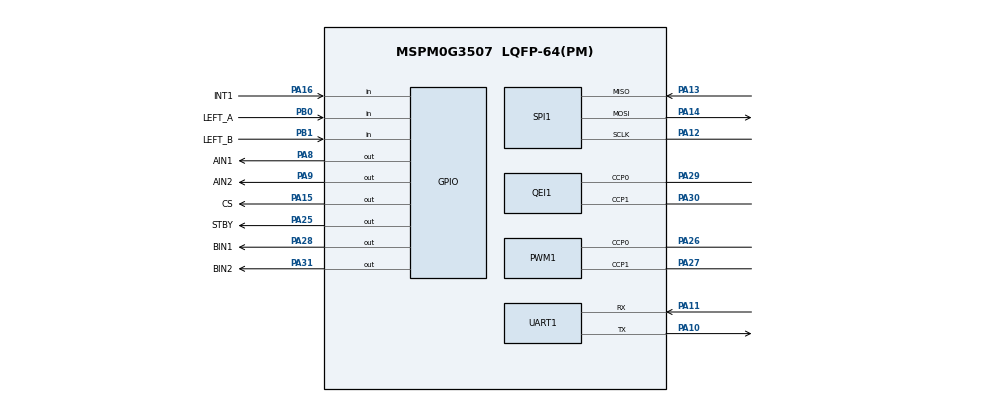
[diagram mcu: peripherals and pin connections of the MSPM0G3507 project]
//@cliArgs --device "MSPM0G350X" --package "LQFP-64(PM)" --part "Default"
//@v2CliArgs --device "MSPM0G3507" --package "LQFP-64(PM)"

/**
 * Import the modules used in this configuration.
 */
const SYSCTL = scripting.addModule("/ti/driverlib/SYSCTL");
const GPIO   = scripting.addModule("/ti/driverlib/GPIO", {}, false);
const GPIO1  = GPIO.addInstance();
const GPIO2  = GPIO.addInstance();
const GPIO3  = GPIO.addInstance();
const PWM    = scripting.addModule("/ti/driverlib/PWM", {}, false);
const PWM1   = PWM.addInstance();
const QEI    = scripting.addModule("/ti/driverlib/QEI", {}, false);
const QEI1   = QEI.addInstance();
const SPI    = scripting.addModule("/ti/driverlib/SPI", {}, false);
const SPI1   = SPI.addInstance();
const TIMER  = scripting.addModule("/ti/driverlib/TIMER", {}, false);
const TIMER1 = TIMER.addInstance();
const TIMER2 = TIMER.addInstance();
const UART   = scripting.addModule("/ti/driverlib/UART", {}, false);
const UART1  = UART.addInstance();
const ProjectConfig = scripting.addModule("/ti/project_config/ProjectConfig");

/**
 * Write custom configuration values to the imported modules.
 */

const Board = scripting.addModule("/ti/driverlib/Board", {}, false);

ProjectConfig.deviceSpin = "MSPM0G3507";

/* TB6612 安全输出：上电全部为低。 */
GPIO1.$name = "MOTOR_GPIO";
GPIO1.associatedPins.create(5);
GPIO1.associatedPins[0].$name        = "STBY";
GPIO1.associatedPins[0].initialValue = "CLEARED";
GPIO1.associatedPins[0].pin.$assign  = "PA25";
GPIO1.associatedPins[1].$name        = "AIN1";
GPIO1.associatedPins[1].initialValue = "CLEARED";
GPIO1.associatedPins[1].pin.$assign  = "PA8";
GPIO1.associatedPins[2].$name        = "AIN2";
GPIO1.associatedPins[2].initialValue = "CLEARED";
GPIO1.associatedPins[2].pin.$assign  = "PA9";
GPIO1.associatedPins[3].$name        = "BIN1";
GPIO1.associatedPins[3].initialValue = "CLEARED";
GPIO1.associatedPins[3].pin.$assign  = "PA28";
GPIO1.associatedPins[4].$name        = "BIN2";
GPIO1.associatedPins[4].initialValue = "CLEARED";
GPIO1.associatedPins[4].pin.$assign  = "PA31";

/* Left AB encoder: GPIOB both-edge interrupts with internal pull-ups. */
GPIO2.$name = "ENCODER_GPIO";
GPIO2.associatedPins.create(2);
GPIO2.associatedPins[0].$name            = "LEFT_A";
GPIO2.associatedPins[0].direction        = "INPUT";
GPIO2.associatedPins[0].internalResistor = "PULL_UP";
GPIO2.associatedPins[0].interruptEn      = true;
GPIO2.associatedPins[0].polarity         = "RISE_FALL";
GPIO2.associatedPins[0].pin.$assign      = "PB0";
GPIO2.associatedPins[1].$name            = "LEFT_B";
GPIO2.associatedPins[1].direction        = "INPUT";
GPIO2.associatedPins[1].internalResistor = "PULL_UP";
GPIO2.associatedPins[1].interruptEn      = true;
GPIO2.associatedPins[1].polarity         = "RISE_FALL";
GPIO2.associatedPins[1].pin.$assign      = "PB1";

/* ICM42688-P: software-controlled nCS plus an input-only INT1 pin. */
GPIO3.$name = "IMU_GPIO";
GPIO3.associatedPins.create(2);
GPIO3.associatedPins[0].$name        = "CS";
GPIO3.associatedPins[0].initialValue = "SET";
GPIO3.associatedPins[0].pin.$assign  = "PA15";
GPIO3.associatedPins[1].$name        = "INT1";
GPIO3.associatedPins[1].direction    = "INPUT";
GPIO3.associatedPins[1].pin.$assign  = "PA16";

/*
 * SPI0 drives the four electrical signals SCLK, MOSI, MISO and GPIO nCS.
 * MSPM0 uses its MOTO3 frame setting when chip select is controlled by GPIO.
 */
SPI1.$name                      = "IMU_SPI";
SPI1.frameFormat                = "MOTO3";
SPI1.polarity                   = "0";
SPI1.phase                      = "0";
SPI1.dataSize                   = 8;
SPI1.bitOrder                   = "MSB";
SPI1.targetBitRate              = 1000000;
SPI1.peripheral.$assign         = "SPI0";
SPI1.peripheral.sclkPin.$assign = "PA12";
SPI1.peripheral.mosiPin.$assign = "PA14";
SPI1.peripheral.misoPin.$assign = "PA13";

/* Right AB encoder: TIMG8 hardware QEI avoids high-rate GPIO interrupts. */
QEI1.$name                      = "RIGHT_ENCODER_QEI";
QEI1.loadValue                  = 65535;
QEI1.peripheral.$assign         = "TIMG8";
QEI1.peripheral.ccp0Pin.$assign = "PA29";
QEI1.peripheral.ccp1Pin.$assign = "PA30";

/* 32 MHz BUSCLK / 1600 = 20 kHz，边沿对齐，初始占空比 0。 */
PWM1.$name                      = "MOTOR_PWM";
PWM1.timerCount                 = 1600;
PWM1.peripheral.$assign         = "TIMG7";
PWM1.peripheral.ccp0Pin.$assign = "PA26";
PWM1.peripheral.ccp1Pin.$assign = "PA27";
PWM1.PWM_CHANNEL_0.$name        = "LEFT_PWM";
PWM1.PWM_CHANNEL_0.dutyCycle    = 0;
PWM1.PWM_CHANNEL_1.$name        = "RIGHT_PWM";
PWM1.PWM_CHANNEL_1.dutyCycle    = 0;

/* 100 Hz 控制定时器，不引出外部引脚。 */
TIMER1.$name              = "CONTROL_TIMER";
TIMER1.timerMode          = "PERIODIC";
TIMER1.timerPeriod        = "10 ms";
TIMER1.timerClkPrescale   = 8;
TIMER1.interrupts         = ["ZERO"];
TIMER1.peripheral.$assign = "TIMG0";

/* 500 Hz IMU acquisition; lower priority than the existing motor loop. */
TIMER2.$name              = "IMU_SAMPLE_TIMER";
TIMER2.timerMode          = "PERIODIC";
TIMER2.timerPeriod        = "2 ms";
TIMER2.interrupts         = ["ZERO"];
TIMER2.interruptPriority  = "2";
TIMER2.peripheral.$assign = "TIMG6";

/* 板载 CH340：UART0, PA10/PA11, 115200 8N1, RX 中断。 */
UART1.$name                      = "DEBUG_UART";
UART1.profile                    = "CONFIG_PROFILE_1";
UART1.peripheral.$assign         = "UART0";
UART1.targetBaudRate             = 115200;
UART1.enableInternalLoopback     = false;
UART1.enabledInterrupts          = ["RX"];
UART1.enableFIFO                 = false;
UART1.peripheral.txPin.$assign   = "PA10";
UART1.peripheral.rxPin.$assign   = "PA11";

SYSCTL.forceDefaultClkConfig = true;
SYSCTL.clockTreeEn           = true;
